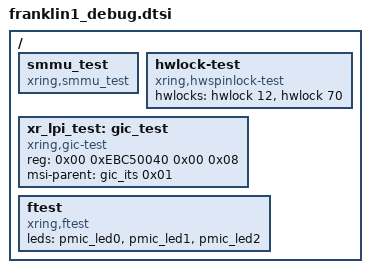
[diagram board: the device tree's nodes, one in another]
// SPDX-License-Identifier: (GPL-2.0+ OR MIT)
/*
 * Copyright 2022 XiaoMi
 */
#include "xring_o1_pmic.dtsi"

/ {
    smmu_test {
        compatible = "xring,smmu_test";
        status = "okay";
    };

    hwlock-test {
        compatible = "xring,hwspinlock-test";
        hwlocks = <&hwlock 12>, <&hwlock 70>;
        status = "okay";
    };

    xr_lpi_test: gic_test {
        compatible = "xring,gic-test";
        reg = <0x00 0xEBC50040 0x00 0x08>;
        msi-parent = <&gic_its 0x01>;
    };

    ftest {
        compatible = "xring,ftest";
        leds = <&pmic_led0>,<&pmic_led1>,<&pmic_led2>;
    };
};
